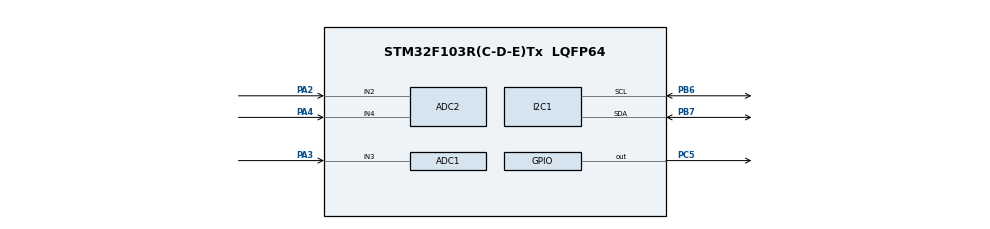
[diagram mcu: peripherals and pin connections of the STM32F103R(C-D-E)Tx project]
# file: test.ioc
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ADC1.Channel-0\#ChannelRegularConversion=ADC_CHANNEL_3
ADC1.NbrOfConversionFlag=1
ADC1.Rank-0\#ChannelRegularConversion=1
ADC1.SamplingTime-0\#ChannelRegularConversion=ADC_SAMPLETIME_1CYCLE_5
ADC1.master=1
ADC2.Channel-0\#ChannelRegularConversion=ADC_CHANNEL_2
ADC2.NbrOfConversionFlag=1
ADC2.Rank-0\#ChannelRegularConversion=1
ADC2.SamplingTime-0\#ChannelRegularConversion=ADC_SAMPLETIME_1CYCLE_5
I2C1.I2C_Mode=I2C_Fast
Mcu.Family=STM32F1
Mcu.Name=STM32F103R(C-D-E)Tx
Mcu.Package=LQFP64
NVIC.PriorityGroup=NVIC_PRIORITYGROUP_4
PA13.Mode=Serial_Wire
PA13.Signal=SYS_JTMS-SWDIO
PA14.Mode=Serial_Wire
PA14.Signal=SYS_JTCK-SWCLK
PA2.Signal=ADCx_IN2
PA3.Signal=ADCx_IN3
PA4.Signal=ADCx_IN4
PB6.GPIO_Speed=GPIO_SPEED_FREQ_HIGH
PB6.Mode=I2C
PB6.Signal=I2C1_SCL
PB7.GPIO_Speed=GPIO_SPEED_FREQ_HIGH
PB7.Mode=I2C
PB7.Signal=I2C1_SDA
PC14-OSC32_IN.Mode=LSE-External-Oscillator
PC14-OSC32_IN.Signal=RCC_OSC32_IN
PC15-OSC32_OUT.Mode=LSE-External-Oscillator
PC15-OSC32_OUT.Signal=RCC_OSC32_OUT
PC5.PinState=GPIO_PIN_SET
PC5.Signal=GPIO_Output
PD0-OSC_IN.Mode=HSE-External-Oscillator
PD0-OSC_IN.Signal=RCC_OSC_IN
PD1-OSC_OUT.Mode=HSE-External-Oscillator
PD1-OSC_OUT.Signal=RCC_OSC_OUT
ProjectManager.HeapSize=0x200
ProjectManager.StackSize=0x400
ProjectManager.TargetToolchain=STM32CubeIDE
RCC.APB1Freq_Value=8000000
RCC.APB2Freq_Value=8000000
SH.ADCx_IN2.0=ADC1_IN2
SH.ADCx_IN2.1=ADC2_IN2,IN2
SH.ADCx_IN3.0=ADC1_IN3,IN3
SH.ADCx_IN3.1=ADC3_IN3
SH.ADCx_IN4.0=ADC2_IN4,IN4
board=custom

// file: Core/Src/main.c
/* USER CODE BEGIN Header */
/**
 ******************************************************************************
 * @file           : main.c
 * @brief          : Main program body
 ******************************************************************************
 * @attention
 *
 * Copyright (c) 2023 STMicroelectronics.
 * All rights reserved.
 *
 * This software is licensed under terms that can be found in the LICENSE file
 * in the root directory of this software component.
 * If no LICENSE file comes with this software, it is provided AS-IS.
 *
 ******************************************************************************
 */
/* USER CODE END Header */
#include "main.h"
#include "fonts.h"
#include "ssd1306.h"
#include "nike.h"
#include "chanel.h"

ADC_HandleTypeDef hadc1;
ADC_HandleTypeDef hadc2;

I2C_HandleTypeDef hi2c1;

void SystemClock_Config(void);
static void MX_GPIO_Init(void);
static void MX_I2C1_Init(void);
static void MX_ADC1_Init(void);
static void MX_ADC2_Init(void);

int main(void) {

	/* MCU Configuration--------------------------------------------------------*/

	/* Reset of all peripherals, Initializes the Flash interface and the Systick. */
	HAL_Init();

	/* Configure the system clock */
	SystemClock_Config();

	/* Initialize all configured peripherals */
	MX_GPIO_Init();
	MX_I2C1_Init();
	MX_ADC1_Init();
	MX_ADC2_Init();
	/* USER CODE BEGIN 2 */

	SSD1306_Init();

	/* USER CODE END 2 */

	/* Infinite loop */
	/* USER CODE BEGIN WHILE */
	while (1) {
		// temperature sensor

		SSD1306_Clear();
		SSD1306_DrawBitmap(0, 0, gImage_chanel, 90, 50, SSD1306_COLOR_WHITE);

		SSD1306_UpdateScreen();

		HAL_Delay(2000);
		SSD1306_Clear();

		uint16_t value_temp;
		HAL_ADCEx_Calibration_Start(&hadc1);
		float t;

		HAL_ADC_Start(&hadc1);
		HAL_ADC_PollForConversion(&hadc1, 1000);
		value_temp = HAL_ADC_GetValue(&hadc1);
		t = (value_temp / 4096.0) * 3.3 * 100.0;

		// Light sensor
		uint16_t value_light;

		HAL_ADCEx_Calibration_Start(&hadc2);
		float k;

		HAL_ADC_Start(&hadc2);
		HAL_ADC_PollForConversion(&hadc2, 1000);
		value_light = HAL_ADC_GetValue(&hadc2);
		k = (value_light / 4096.0) * 3.3 * 100.0;

		// Den sang khi cam bien anh sang thay khong có anh sang

		if (k < 45) {
			HAL_GPIO_WritePin(GPIOC, GPIO_PIN_5, GPIO_PIN_SET);
			SSD1306_Puts("*", &Font_11x18, 1);
			SSD1306_GotoXY(30, 50);
		} else {
			HAL_GPIO_WritePin(GPIOC, GPIO_PIN_5, GPIO_PIN_RESET);
		}

		// Chuyển nhiệt độ thành chuỗi và hiển thị lên màn hình
		char snum_temp[10];
		char snum_light[10];

		sprintf(snum_temp, "%.2f", t);

		sprintf(snum_light, "%.2f", k);

		SSD1306_GotoXY(0, 0);
		SSD1306_Puts("TEMP:", &Font_11x18, 1);
		SSD1306_GotoXY(60, 0);
		SSD1306_Puts(snum_temp, &Font_11x18, 1);

		SSD1306_GotoXY(0, 30);
		SSD1306_Puts("LIGHT:", &Font_11x18, 1);
		SSD1306_GotoXY(60, 30);
		SSD1306_Puts(snum_light, &Font_11x18, 1);

		SSD1306_UpdateScreen();
		HAL_Delay(1000);
	}

	/* USER CODE END 3 */
}

void SystemClock_Config(void) {
	RCC_OscInitTypeDef RCC_OscInitStruct = { 0 };
	RCC_ClkInitTypeDef RCC_ClkInitStruct = { 0 };
	RCC_PeriphCLKInitTypeDef PeriphClkInit = { 0 };

	/** Initializes the RCC Oscillators according to the specified parameters
	 * in the RCC_OscInitTypeDef structure.
	 */
	RCC_OscInitStruct.OscillatorType = RCC_OSCILLATORTYPE_HSI;
	RCC_OscInitStruct.HSIState = RCC_HSI_ON;
	RCC_OscInitStruct.HSICalibrationValue = RCC_HSICALIBRATION_DEFAULT;
	RCC_OscInitStruct.PLL.PLLState = RCC_PLL_NONE;
	if (HAL_RCC_OscConfig(&RCC_OscInitStruct) != HAL_OK) {
		Error_Handler();
	}

	/** Initializes the CPU, AHB and APB buses clocks
	 */
	RCC_ClkInitStruct.ClockType = RCC_CLOCKTYPE_HCLK | RCC_CLOCKTYPE_SYSCLK
			| RCC_CLOCKTYPE_PCLK1 | RCC_CLOCKTYPE_PCLK2;
	RCC_ClkInitStruct.SYSCLKSource = RCC_SYSCLKSOURCE_HSI;
	RCC_ClkInitStruct.AHBCLKDivider = RCC_SYSCLK_DIV1;
	RCC_ClkInitStruct.APB1CLKDivider = RCC_HCLK_DIV1;
	RCC_ClkInitStruct.APB2CLKDivider = RCC_HCLK_DIV1;

	if (HAL_RCC_ClockConfig(&RCC_ClkInitStruct, FLASH_LATENCY_0) != HAL_OK) {
		Error_Handler();
	}
	PeriphClkInit.PeriphClockSelection = RCC_PERIPHCLK_ADC;
	PeriphClkInit.AdcClockSelection = RCC_ADCPCLK2_DIV2;
	if (HAL_RCCEx_PeriphCLKConfig(&PeriphClkInit) != HAL_OK) {
		Error_Handler();
	}
}

static void MX_ADC1_Init(void) {

	ADC_ChannelConfTypeDef sConfig = { 0 };

	/** Common config
	 */
	hadc1.Instance = ADC1;
	hadc1.Init.ScanConvMode = ADC_SCAN_DISABLE;
	hadc1.Init.ContinuousConvMode = DISABLE;
	hadc1.Init.DiscontinuousConvMode = DISABLE;
	hadc1.Init.ExternalTrigConv = ADC_SOFTWARE_START;
	hadc1.Init.DataAlign = ADC_DATAALIGN_RIGHT;
	hadc1.Init.NbrOfConversion = 1;
	if (HAL_ADC_Init(&hadc1) != HAL_OK) {
		Error_Handler();
	}

	/** Configure Regular Channel
	 */
	sConfig.Channel = ADC_CHANNEL_3;
	sConfig.Rank = ADC_REGULAR_RANK_1;
	sConfig.SamplingTime = ADC_SAMPLETIME_1CYCLE_5;
	if (HAL_ADC_ConfigChannel(&hadc1, &sConfig) != HAL_OK) {
		Error_Handler();
	}

}

static void MX_ADC2_Init(void) {

	ADC_ChannelConfTypeDef sConfig = { 0 };

	/** Common config
	 */
	hadc2.Instance = ADC2;
	hadc2.Init.ScanConvMode = ADC_SCAN_DISABLE;
	hadc2.Init.ContinuousConvMode = DISABLE;
	hadc2.Init.DiscontinuousConvMode = DISABLE;
	hadc2.Init.ExternalTrigConv = ADC_SOFTWARE_START;
	hadc2.Init.DataAlign = ADC_DATAALIGN_RIGHT;
	hadc2.Init.NbrOfConversion = 1;
	if (HAL_ADC_Init(&hadc2) != HAL_OK) {
		Error_Handler();
	}

	/** Configure Regular Channel
	 */
	sConfig.Channel = ADC_CHANNEL_2;
	sConfig.Rank = ADC_REGULAR_RANK_1;
	sConfig.SamplingTime = ADC_SAMPLETIME_1CYCLE_5;
	if (HAL_ADC_ConfigChannel(&hadc2, &sConfig) != HAL_OK) {
		Error_Handler();
	}

}

static void MX_I2C1_Init(void) {

	hi2c1.Instance = I2C1;
	hi2c1.Init.ClockSpeed = 400000;
	hi2c1.Init.DutyCycle = I2C_DUTYCYCLE_2;
	hi2c1.Init.OwnAddress1 = 0;
	hi2c1.Init.AddressingMode = I2C_ADDRESSINGMODE_7BIT;
	hi2c1.Init.DualAddressMode = I2C_DUALADDRESS_DISABLE;
	hi2c1.Init.OwnAddress2 = 0;
	hi2c1.Init.GeneralCallMode = I2C_GENERALCALL_DISABLE;
	hi2c1.Init.NoStretchMode = I2C_NOSTRETCH_DISABLE;
	if (HAL_I2C_Init(&hi2c1) != HAL_OK) {
		Error_Handler();
	}

}

static void MX_GPIO_Init(void) {
	GPIO_InitTypeDef GPIO_InitStruct = { 0 };

	/* GPIO Ports Clock Enable */
	__HAL_RCC_GPIOC_CLK_ENABLE();
	__HAL_RCC_GPIOD_CLK_ENABLE();
	__HAL_RCC_GPIOA_CLK_ENABLE();
	__HAL_RCC_GPIOB_CLK_ENABLE();

	/*Configure GPIO pin Output Level */
	HAL_GPIO_WritePin(GPIOC, GPIO_PIN_5, GPIO_PIN_SET);

	/*Configure GPIO pin : PA3 */
	GPIO_InitStruct.Pin = GPIO_PIN_3;
	GPIO_InitStruct.Mode = GPIO_MODE_ANALOG;
	HAL_GPIO_Init(GPIOA, &GPIO_InitStruct);

	/*Configure GPIO pin : PC5 */
	GPIO_InitStruct.Pin = GPIO_PIN_5;
	GPIO_InitStruct.Mode = GPIO_MODE_OUTPUT_PP;
	GPIO_InitStruct.Pull = GPIO_NOPULL;
	GPIO_InitStruct.Speed = GPIO_SPEED_FREQ_LOW;
	HAL_GPIO_Init(GPIOC, &GPIO_InitStruct);

}

void Error_Handler(void) {
	__disable_irq();
	while (1) {
	}
}
